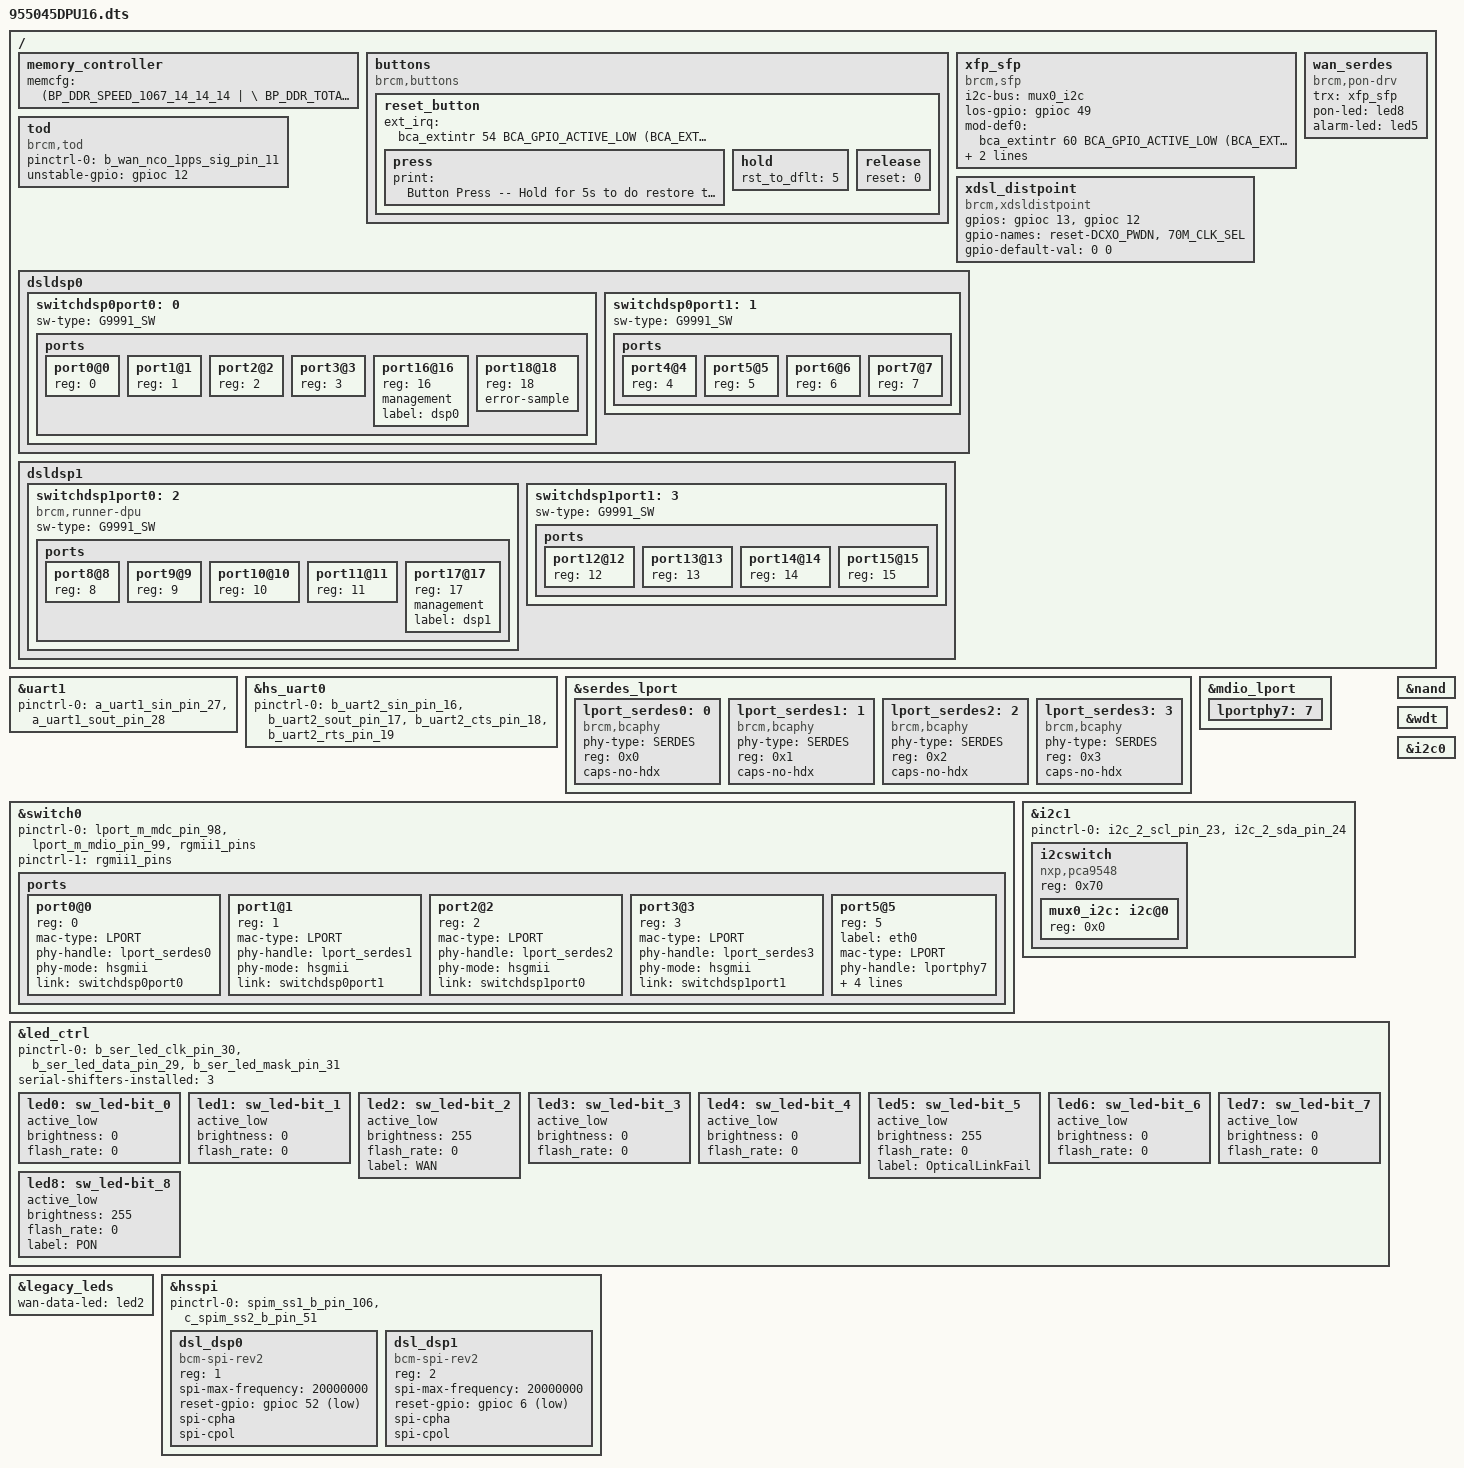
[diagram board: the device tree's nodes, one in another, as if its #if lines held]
#include "inc/55045.dtsi"

/ {
    memory_controller {
        memcfg = <(BP_DDR_SPEED_1067_14_14_14 | \
                   BP_DDR_TOTAL_SIZE_512MB    | \
                   BP_DDR_DEVICE_WIDTH_16     | \
                   BP_DDR_TOTAL_WIDTH_32BIT)>;
    };
};

/ {
    buttons {
        compatible = "brcm,buttons";
        reset_button {
            ext_irq = <&bca_extintr 54 BCA_GPIO_ACTIVE_LOW (BCA_EXTINTR_TYPE_LOW_LEVEL | BCA_EXTINTR_TYPE_SENSE_EDGE)>;
            press {
                print = "Button Press -- Hold for 5s to do restore to default";
   			};
            hold {
                rst_to_dflt = <5>;
            };
            release {
                reset = <0>;
            };	
        };
    };

    xfp_sfp: xfp_sfp {
        compatible = "brcm,sfp";
        i2c-bus = <&mux0_i2c>;
        los-gpio = <&gpioc 49 GPIO_ACTIVE_HIGH>;
        mod-def0 = <&bca_extintr 60 BCA_GPIO_ACTIVE_LOW (BCA_EXTINTR_TYPE_BOTH_EDGE | BCA_EXTINTR_TYPE_SENSE_EDGE)>;
        tx-power-gpio = <&gpioc 50 GPIO_ACTIVE_HIGH>;
        tx-power-down-gpio = <&gpioc 55 GPIO_ACTIVE_HIGH>;
    };

    wan_serdes {
            compatible = "brcm,pon-drv";
            trx = <&xfp_sfp>;
            pon-led = <&led8>;
            alarm-led = <&led5>;
    };

    tod {
        compatible = "brcm,tod";
        pinctrl-names = "default";
        pinctrl-0 = <&b_wan_nco_1pps_sig_pin_11>;

        unstable-gpio = <&gpioc 12 GPIO_ACTIVE_HIGH>;
    };

    xdsl_distpoint {
        compatible = "brcm,xdsldistpoint";
        gpios = <&gpioc 13 GPIO_ACTIVE_HIGH>, <&gpioc 12 GPIO_ACTIVE_HIGH>;
        gpio-names = "reset-DCXO_PWDN", "70M_CLK_SEL";
        gpio-default-val = <0 0>;
        // gpio-value-names-1 = "XO", "DCXO";
    };

    dsldsp0: dsldsp0 {
        /* Defined below */
    };

    dsldsp1: dsldsp1 {
        /* Defined below */
    };
};

#ifdef CONFIG_BCM_TIME_SYNC_MODULE
    /* UART 2*/
	&uart1 {
		pinctrl-0 = <&a_uart1_sin_pin_27 &a_uart1_sout_pin_28>;
	    status = "okay";
	};
#endif

&hs_uart0 {
    pinctrl-0 = <&b_uart2_sin_pin_16 &b_uart2_sout_pin_17 &b_uart2_cts_pin_18 &b_uart2_rts_pin_19>;
	status = "okay";
};

&dsldsp0 {
        switchdsp0port0:0 {
                sw-type = "G9991_SW";

                ports {
                        #address-cells = <1>;
                        #size-cells = <0>;

                        port0@0 {
                                reg = <0>;
                        };

                        port1@1 {
                                reg = <1>;
                        };

                        port2@2 {
                                reg = <2>;
                        };

                        port3@3 {
                                reg = <3>;
                        };

                        port16@16 {
                                reg = <16>;
                                management;
                                label = "dsp0";
                        };

                        port18@18 {
                                reg = <18>;
                                error-sample;
                        };
                };
        };

        switchdsp0port1:1 {
                sw-type = "G9991_SW";

                ports {
                        #address-cells = <1>;
                        #size-cells = <0>;

                        port4@4 {
                                reg = <4>;
                        };

                        port5@5 {
                                reg = <5>;
                        };

                        port6@6 {
                                reg = <6>;
                        };

                        port7@7 {
                                reg = <7>;
                        };
                };
        };
};

&dsldsp1 {
        switchdsp1port0:2 {
                compatible = "brcm,runner-dpu";
                sw-type = "G9991_SW";

                ports {
                        #address-cells = <1>;
                        #size-cells = <0>;

                        port8@8 {
                                reg = <8>;
                        };

                        port9@9 {
                                reg = <9>;
                        };

                        port10@10 {
                                reg = <10>;
                        };

                        port11@11 {
                                reg = <11>;
                        };

                        port17@17 {
                                reg = <17>;
                                management;
                                label = "dsp1";
                        };
                };
        };

        switchdsp1port1:3 {
                sw-type = "G9991_SW";

                ports {
                        #address-cells = <1>;
                        #size-cells = <0>;

                        port12@12 {
                                reg = <12>;
                        };

                        port13@13 {
                                reg = <13>;
                        };

                        port14@14 {
                                reg = <14>;
                        };

                        port15@15 {
                                reg = <15>;
                        };
                };
        };
};

&serdes_lport {
        lport_serdes0:0 {
                compatible = "brcm,bcaphy";
                phy-type = "SERDES";
                reg = <0x0>;
                caps-no-hdx;
        };

        lport_serdes1:1 {
                compatible = "brcm,bcaphy";
                phy-type = "SERDES";
                reg = <0x1>;
                caps-no-hdx;
        };

        lport_serdes2:2 {
                compatible = "brcm,bcaphy";
                phy-type = "SERDES";
                reg = <0x2>;
                caps-no-hdx;
        };

        lport_serdes3:3 {
                compatible = "brcm,bcaphy";
                phy-type = "SERDES";
                reg = <0x3>;
                caps-no-hdx;
        };
};

&mdio_lport {
        lportphy7:7 {
                status = "okay";
        };
};

&switch0 {
        pinctrl-names = "default", "rgmii1";
        pinctrl-0 = <&lport_m_mdc_pin_98 &lport_m_mdio_pin_99 &rgmii1_pins>;
        pinctrl-1 = <&rgmii1_pins>;

        /delete-node/ ports;
        ports {
                #address-cells = <1>;
                #size-cells = <0>;

                port0@0 {
                        reg = <0>;
                        mac-type = "LPORT";
                        phy-handle = <&lport_serdes0>;
                        phy-mode = "hsgmii";
                        link = <&switchdsp0port0>;
                };

                port1@1 {
                        reg = <1>;
                        mac-type = "LPORT";
                        phy-handle = <&lport_serdes1>;
                        phy-mode = "hsgmii";
                        link = <&switchdsp0port1>;
                };

                port2@2 {
                        reg = <2>;
                        mac-type = "LPORT";
                        phy-handle = <&lport_serdes2>;
                        phy-mode = "hsgmii";
                        link = <&switchdsp1port0>;
                };

                port3@3 {
                        reg = <3>;
                        mac-type = "LPORT";
                        phy-handle = <&lport_serdes3>;
                        phy-mode = "hsgmii";
                        link = <&switchdsp1port1>;
                };

                port5@5 {
                        reg = <5>;
                        label = "eth0";
                        mac-type = "LPORT";
                        phy-handle = <&lportphy7>;
                        phy-mode = "rgmii";
                        tx-delay;
                        management;
                        mii-pinctrl-state = "rgmii1";
                };
        };
};

&i2c1 {
    i2cswitch {
        compatible = "nxp,pca9548";
        #address-cells = <1>;
        #size-cells = <0>;
        reg = <0x70>;

        mux0_i2c: i2c@0 {
            reg = <0x0>;
        };
    };
};

&led_ctrl {
    pinctrl-names = "default";
    pinctrl-0 = <&b_ser_led_clk_pin_30 &b_ser_led_data_pin_29 &b_ser_led_mask_pin_31>;
    serial-shifters-installed = <3>;

    led0: sw_led-bit_0 {
              active_low; 
              brightness = <0>;
              flash_rate = <0>;
              status = "okay";
          };
    led1: sw_led-bit_1 {
              active_low; 
              brightness = <0>;
              flash_rate = <0>;
              status = "okay";
          };
    led2: sw_led-bit_2 {
              active_low; 
              brightness = <255>;
              flash_rate = <0>;
              status = "okay";
              label = "WAN";
          };
    led3: sw_led-bit_3 {
              active_low; 
              brightness = <0>;
              flash_rate = <0>;
              status = "okay";
          };
    led4: sw_led-bit_4 {
              active_low; 
              brightness = <0>;
              flash_rate = <0>;
              status = "okay";
          };
    led5: sw_led-bit_5 {
              active_low; 
              brightness = <255>;
              flash_rate = <0>;
              status = "okay";
              label = "OpticalLinkFail";
          };
    led6: sw_led-bit_6 {
              active_low; 
              brightness = <0>;
              flash_rate = <0>;
              status = "okay";
          };
    led7: sw_led-bit_7 {
              active_low; 
              brightness = <0>;
              flash_rate = <0>;
              status = "okay";
          };

    led8: sw_led-bit_8 {
              active_low; 
              brightness = <255>;
              flash_rate = <0>;
              status = "okay";
              label = "PON";
          };
};

&legacy_leds {
    wan-data-led = <&led2>;
};

&hsspi {
    pinctrl-names="default";
    pinctrl-0 = <&spim_ss1_b_pin_106 &c_spim_ss2_b_pin_51>;
    status = "okay";

    #address-cells = <1>;
    #size-cells = <0>;

    dsl_dsp0 {
        compatible = "bcm-spi-rev2";
        reg = <1>; /* chip select 1 */
        spi-max-frequency = <20000000>;
        reset-gpio = <&gpioc 52 GPIO_ACTIVE_LOW>;
        spi-cpha;
        spi-cpol;
    };

    dsl_dsp1 {
        compatible = "bcm-spi-rev2";
        reg = <2>; /* chip select 2 */
        spi-max-frequency = <20000000>;
        reset-gpio = <&gpioc 6 GPIO_ACTIVE_LOW>;
        spi-cpha;
        spi-cpol;
    };
};

&nand {
	status = "okay";
};
&wdt {
	status = "okay";
};
&i2c0 {
    status = "okay";
};
&i2c1 {
    pinctrl-0 = <&i2c_2_scl_pin_23 &i2c_2_sda_pin_24>;
    pinctrl-names = "default";
    status = "okay";
};

